AUTOSAR XML (schema 4-2-1)
package /VehicleProject
  system System
package /NM
  nm config NmConfig: can-nm-cluster-coupling=coupled-cluster=[CAN00_CAN, CAN01_CAN]
    can nm cluster CAN00_CAN: communication-cluster=CAN00, nm-channel-id=0, nm-msg-cycle-time=0.1, nm-network-timeout=1, nm-repeat-message-time=0.4, nm-user-data-length=6, nm-wait-bus-sleep-time=0.75
      can nm node MyECU: controller=CT_CAN00, nm-if-ecu=MyECU_CAN, nm-node-id=0, rx-nm-pdu=msg_nm_RearECU_oCAN00, tx-nm-pdu=msg_nm_MyECU_oCAN00, nm-msg-cycle-offset=0, nm-msg-reduced-time=0.05, nm-range-config={lower-can-id=1024, upper-can-id=1087}
      can nm node RearECU: nm-if-ecu=RearECU_CAN, nm-node-id=1, rx-nm-pdu=msg_nm_MyECU_oCAN00, tx-nm-pdu=msg_nm_RearECU_oCAN00, nm-msg-cycle-offset=0, nm-msg-reduced-time=0.05, nm-range-config={lower-can-id=1024, upper-can-id=1087}
      can nm node Tester: nm-if-ecu=Tester_CAN, nm-node-id=0, nm-passive-mode-enabled=true, nm-msg-cycle-offset=0, nm-msg-reduced-time=0.05, nm-range-config={lower-can-id=1024, upper-can-id=1087}
    can nm cluster CAN01_CAN: communication-cluster=CAN01, nm-channel-id=1, nm-msg-cycle-time=0.1, nm-network-timeout=1, nm-repeat-message-time=0.4, nm-user-data-length=6, nm-wait-bus-sleep-time=0.75
      can nm node RearECU: nm-if-ecu=RearECU_CAN, nm-node-id=1, nm-passive-mode-enabled=true, nm-msg-cycle-offset=0, nm-msg-reduced-time=0.05, nm-range-config={lower-can-id=1024, upper-can-id=1087}
      can nm node Tester: nm-if-ecu=Tester_CAN, nm-node-id=0, nm-passive-mode-enabled=true, nm-msg-cycle-offset=0, nm-msg-reduced-time=0.05, nm-range-config={lower-can-id=1024, upper-can-id=1087}
    nm-if-ecus:
      nm ecu MyECU_CAN: ecu-instance=MyECU, nm-node-id-enabled=true, nm-user-data-enabled=true
      nm ecu RearECU_CAN: nm-node-id-enabled=true, nm-passive-mode-enabled=true, nm-user-data-enabled=true
      nm ecu Tester_CAN: nm-node-id-enabled=true, nm-passive-mode-enabled=true, nm-user-data-enabled=true
package /TP
  can tp config CAN00_CAN: communication-cluster=CAN00, can-tp-ecu{cycle-time-main-function=0.005, ecu-instance=MyECU}
    can tp channel TPCH: channel-id=0, channel-mode=FULL-DUPLEX-MODE
    can-tp-connection addressing-format=STANDARD, can-tp-channel=TPCH, data-pdu=msg_diag_RequestGlobal_Tp_oCAN00, receiver=CAN00_CAN/TN_MyECU, ta-type=FUNCTIONAL, tp-sdu=msg_diag_RequestGlobal_oCAN00, transmitter=TN_Tester:
      ident msg_diag_RequestGlobal_oTN_Tester
    can-tp-connection addressing-format=STANDARD, can-tp-channel=TPCH, data-pdu=msg_diag_Request_MyECU_Tp_oCAN00, flow-control-pdu=msg_diag_Response_MyECU_Tp_oCAN00, receiver=CAN00_CAN/TN_MyECU, ta-type=PHYSICAL, tp-sdu=msg_diag_Request_MyECU_oCAN00, transmitter=TN_Tester:
      ident msg_diag_Request_MyECU_oTN_MyECU
    can-tp-connection addressing-format=STANDARD, can-tp-channel=TPCH, data-pdu=msg_diag_Response_MyECU_Tp_oCAN00, flow-control-pdu=msg_diag_Request_MyECU_Tp_oCAN00, receiver=TN_Tester, ta-type=PHYSICAL, tp-sdu=msg_diag_Response_MyECU_oCAN00, transmitter=CAN00_CAN/TN_MyECU:
      ident msg_diag_Response_MyECU_oTN_MyECU
    can tp node TN_MyECU: connector=CN_CAN00
    can tp node TN_Tester
  can tp config CAN01_CAN: communication-cluster=CAN01, can-tp-ecu{cycle-time-main-function=0.005, ecu-instance=MyECU}
    can tp node TN_MyECU: connector=CN_CAN01
package /Cluster
  can cluster CAN00: protocol-name=CAN  # CAN1
    can physical channel CHNL: comm-connectors=CN_CAN00
      frame msg_diag_Request_MyECU_oCAN00: id 0x610, to MyECU, frame-length=8, can-addressing-mode=STANDARD
        n pdu msg_diag_Request_MyECU_Tp_oCAN00: length=8
      frame msg_diag_RequestGlobal_oCAN00: id 0x614, to MyECU, frame-length=8, can-addressing-mode=STANDARD
        n pdu msg_diag_RequestGlobal_Tp_oCAN00: length=8
      frame msg_diag_Response_MyECU_oCAN00: id 0x612, from MyECU, frame-length=8, can-addressing-mode=STANDARD
        n pdu msg_diag_Response_MyECU_Tp_oCAN00: length=8
      frame msg_MyECU_Lamp_oCAN00: id 0x511, from MyECU, frame-length=8, can-addressing-mode=STANDARD
        pdu msg_MyECU_Lamp_oCAN00: length=8, minimum-delay=0, transmission-mode-false-timing=cyclic-timing={time-offset=0, time-period=0.1}, transmission-mode-true-timing=cyclic-timing={time-offset=0, time-period=0.1}, unused-bit-pattern=0
          signal sig_LampCnt_omsg_MyECU_Lamp_oCAN00: start 7, 8 bit, big-endian, init-value=0, base-type=uint8, compu-method=CM_sig_LampCnt, data-constr=DC_sig_LampCnt, transfer-property=PENDING
      frame msg_nm_MyECU_oCAN00: id 0x400, from MyECU, frame-length=8, can-addressing-mode=STANDARD
        nm pdu msg_nm_MyECU_oCAN00: length=8, unused-bit-pattern=0
      frame msg_nm_RearECU_oCAN00: id 0x401, to MyECU, frame-length=8, can-addressing-mode=STANDARD
        nm pdu msg_nm_RearECU_oCAN00: length=8, unused-bit-pattern=0
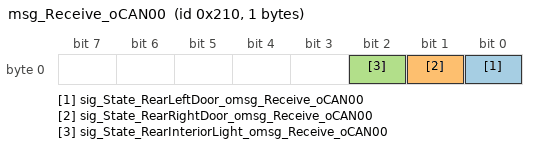
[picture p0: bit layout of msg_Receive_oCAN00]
      frame msg_Receive_oCAN00: id 0x210, to MyECU, frame-length=1, can-addressing-mode=STANDARD
        pdu msg_Receive_oCAN00: length=1, minimum-delay=0, transmission-mode-false-timing=cyclic-timing={time-offset=0, time-period=0.1}, transmission-mode-true-timing=cyclic-timing={time-offset=0, time-period=0.1}, unused-bit-pattern=0
          signal sig_State_RearLeftDoor_omsg_Receive_oCAN00: start 0, 1 bit, little-endian, init-value=0, base-type=boolean, compu-method=CM_sig_State_RearLeftDoor, data-constr=DC_sig_State_RearLeftDoor, transfer-property=PENDING, to MyECU
          signal sig_State_RearRightDoor_omsg_Receive_oCAN00: start 1, 1 bit, little-endian, init-value=0, base-type=boolean, compu-method=CM_sig_State_RearRightDoor, data-constr=DC_sig_State_RearRightDoor, transfer-property=PENDING, to MyECU
          signal sig_State_RearInteriorLight_omsg_Receive_oCAN00: start 2, 1 bit, little-endian, init-value=0, base-type=boolean, compu-method=CM_sig_State_RearInteriorLight, data-constr=DC_sig_State_RearInteriorLight, transfer-property=PENDING, to MyECU
      frame msg_Receive_1_oCAN00: id 0x211, to MyECU, frame-length=1, can-addressing-mode=STANDARD
        pdu msg_Receive_1_oCAN00: length=1, minimum-delay=0, transmission-mode-false-timing=cyclic-timing={time-offset=0, time-period=0.1}, transmission-mode-true-timing=cyclic-timing={time-offset=0, time-period=0.1}, unused-bit-pattern=0
          signal sig_State__Copy_1_omsg_Receive_1_oCAN00: start 0, 1 bit, little-endian, init-value=0, base-type=boolean, compu-method=CM_sig_State__Copy_1, data-constr=DC_sig_State__Copy_1, transfer-property=PENDING, to MyECU
      frame msg_Receive_Extend_1_oCAN00: id 0x18DBFFF9, to MyECU, frame-length=1, can-addressing-mode=EXTENDED
        pdu msg_Receive_Extend_1_oCAN00: length=1, minimum-delay=0, transmission-mode-false-timing=cyclic-timing={time-offset=0, time-period=0.1}, transmission-mode-true-timing=cyclic-timing={time-offset=0, time-period=0.1}, unused-bit-pattern=0
          signal sig_State__Extend_1_omsg_Receive_Extend_1_oCAN00: start 1, 1 bit, little-endian, init-value=0, base-type=boolean, compu-method=CM_sig_State__Extend_1, data-constr=DC_sig_State__Extend_1, transfer-property=PENDING, to MyECU
      frame msg_Transmit_oCAN00: id 0x200, from MyECU, frame-length=1, can-addressing-mode=STANDARD
        pdu msg_Transmit_oCAN00: length=1, minimum-delay=0, transmission-mode-false-timing=cyclic-timing={time-offset=0, time-period=0.1}, transmission-mode-true-timing=cyclic-timing={time-offset=0, time-period=0.1}, unused-bit-pattern=0
          signal sig_RearInteriorLight_omsg_Transmit_oCAN00: start 0, 1 bit, little-endian, init-value=0, base-type=boolean, compu-method=CM_sig_RearInteriorLight, data-constr=DC_sig_RearInteriorLight, transfer-property=PENDING
      frame msg_Transmit_Copy_1_oCAN00: id 0x201, from MyECU, frame-length=8, can-addressing-mode=STANDARD
        pdu msg_Transmit_Copy_1_oCAN00: length=8, minimum-delay=0, transmission-mode-false-timing=cyclic-timing={time-offset=0, time-period=0.1}, transmission-mode-true-timing=cyclic-timing={time-offset=0, time-period=0.1}, unused-bit-pattern=0
          signal sig_RearInteriorLight_Copy_1_omsg_Transmit_Copy_1_oCAN00: start 0, 1 bit, little-endian, init-value=0, base-type=boolean, compu-method=CM_sig_RearInteriorLight_Copy_1, data-constr=DC_sig_RearInteriorLight_Copy_1, transfer-property=PENDING
      frame msg_Transmit_Extended1_oCAN00: id 0x18DAF913, from MyECU, frame-length=8, can-addressing-mode=EXTENDED
        pdu msg_Transmit_Extended1_oCAN00: length=8, minimum-delay=0, transmission-mode-false-timing=cyclic-timing={time-offset=0, time-period=0.1}, transmission-mode-true-timing=cyclic-timing={time-offset=0, time-period=0.1}, unused-bit-pattern=0
          signal sig_RearInteriorLight_Extend_1_omsg_Transmit_Extended1_oCAN00: start 0, 1 bit, little-endian, init-value=0, base-type=boolean, compu-method=CM_sig_RearInteriorLight_Extend_1, data-constr=DC_sig_RearInteriorLight_Extend_1, transfer-property=PENDING
      pdu triggering PT_msg_diag_Request_MyECU: pdu=msg_diag_Request_MyECU_oCAN00, to MyECU
      pdu triggering PT_msg_diag_RequestGlobal: pdu=msg_diag_RequestGlobal_oCAN00, to MyECU
      pdu triggering PT_msg_diag_Response_MyECU: pdu=msg_diag_Response_MyECU_oCAN00, from MyECU
  can cluster CAN01: protocol-name=CAN  # CAN2
    can physical channel CHNL: comm-connectors=CN_CAN01
      frame msg_Receive_Extend_2_oCAN01: id 0x18DBFFF8, to MyECU, frame-length=1, can-addressing-mode=EXTENDED
        pdu msg_Receive_Extend_2_oCAN01: length=1, minimum-delay=0, transmission-mode-false-timing=cyclic-timing={time-offset=0, time-period=0.1}, transmission-mode-true-timing=cyclic-timing={time-offset=0, time-period=0.1}, unused-bit-pattern=0
          signal sig_State__Extend_2_omsg_Receive_Extend_2_oCAN01: start 1, 1 bit, little-endian, init-value=0, base-type=boolean, compu-method=CM_sig_State__Extend_2, data-constr=DC_sig_State__Extend_2, transfer-property=PENDING, to MyECU
      frame msg_Transmit_Extended2_oCAN01: id 0x18DAF914, from MyECU, frame-length=8, can-addressing-mode=EXTENDED
        pdu msg_Transmit_Extended2_oCAN01: length=8, minimum-delay=0, transmission-mode-false-timing=cyclic-timing={time-offset=0, time-period=0.1}, transmission-mode-true-timing=cyclic-timing={time-offset=0, time-period=0.1}, unused-bit-pattern=0
          signal sig_RearInteriorLight_Extend_2_omsg_Transmit_Extended2_oCAN01: start 0, 1 bit, little-endian, init-value=0, base-type=boolean, compu-method=CM_sig_RearInteriorLight_Extend_2, data-constr=DC_sig_RearInteriorLight_Extend_2, transfer-property=PENDING
package /ECU
  ecu instance MyECU: associated-com-i-pdu-group=[MyECU_oCAN00_Rx, MyECU_oCAN00_Tx, MyECU_oCAN01_Rx, MyECU_oCAN01_Tx]
    can communication controller CT_CAN00
    can communication controller CT_CAN01
    can communication connector CN_CAN00: comm-controller=CT_CAN00
    can communication connector CN_CAN01: comm-controller=CT_CAN01
package /Gateway
  gateway MyECU: ecu=MyECU
package /IPDUGroup
  4 x i signal i pdu group:
    MyECU_oCAN00_Rx: communication-direction=IN, i-signal-i-pdus=[msg_Receive_1_oCAN00, msg_Receive_Extend_1_oCAN00, msg_Receive_oCAN00]
    MyECU_oCAN00_Tx: communication-direction=OUT, i-signal-i-pdus=[msg_MyECU_Lamp_oCAN00, msg_Transmit_Copy_1_oCAN00, msg_Transmit_Extended1_oCAN00, msg_Transmit_oCAN00]
    MyECU_oCAN01_Rx: communication-direction=IN, i-signal-i-pdus=msg_Receive_Extend_2_oCAN01
    MyECU_oCAN01_Tx: communication-direction=OUT, i-signal-i-pdus=msg_Transmit_Extended2_oCAN01
package /PDU
  dcm i pdu msg_diag_Request_MyECU_oCAN00: length=8, diag-pdu-type=DIAG-REQUEST
  dcm i pdu msg_diag_RequestGlobal_oCAN00: length=7, diag-pdu-type=DIAG-REQUEST
  dcm i pdu msg_diag_Response_MyECU_oCAN00: length=8, diag-pdu-type=DIAG-RESPONSE
